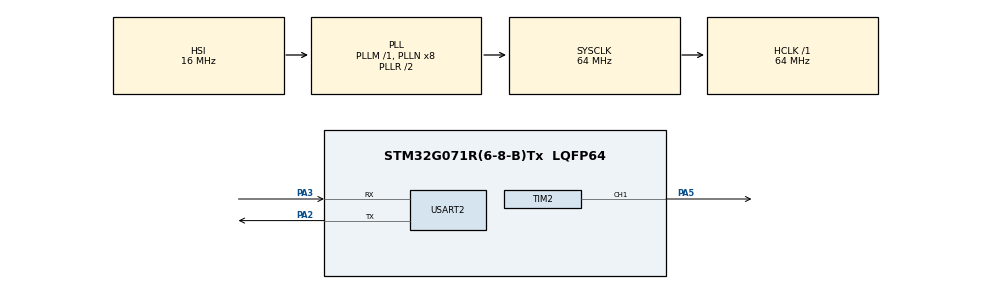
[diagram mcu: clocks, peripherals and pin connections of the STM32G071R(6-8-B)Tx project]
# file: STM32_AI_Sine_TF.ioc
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Mcu.Family=STM32G0
Mcu.Name=STM32G071R(6-8-B)Tx
Mcu.Package=LQFP64
PA2.Mode=Asynchronous
PA2.Signal=USART2_TX
PA3.Mode=Asynchronous
PA3.Signal=USART2_RX
PA5.Signal=S_TIM2_CH1_ETR
ProjectManager.HeapSize=0x200
ProjectManager.StackSize=0x400
ProjectManager.TargetToolchain=STM32CubeIDE
RCC.ADCFreq_Value=64000000
RCC.AHBFreq_Value=64000000
RCC.CortexFreq_Value=64000000
RCC.EXTERNAL_CLOCK_VALUE=48000
RCC.HCLKFreq_Value=64000000
RCC.HSE_VALUE=8000000
RCC.HSI_VALUE=16000000
RCC.LSE_VALUE=32768
RCC.SYSCLKFreq_VALUE=64000000
RCC.SYSCLKSource=RCC_SYSCLKSOURCE_PLLCLK
RCC.VCOOutputFreq_Value=128000000
SH.S_TIM2_CH1_ETR.0=TIM2_CH1,PWM Generation1 CH1
STMicroelectronics.X-CUBE-AI.10.2.0.ActivationBufferSizeList=2324
STMicroelectronics.X-CUBE-AI.10.2.0.ActivationBuffers=pool0
STMicroelectronics.X-CUBE-AI.10.2.0.ActivationNames=pool0
STMicroelectronics.X-CUBE-AI.10.2.0.ActivationSizes=AI_NETWORK_DATA_ACTIVATION_1_SIZE
STMicroelectronics.X-CUBE-AI.10.2.0.ApplicationCcDeviceJjApplication=ApplicationTemplate
STMicroelectronics.X-CUBE-AI.10.2.0.HeapSize=0x800
STMicroelectronics.X-CUBE-AI.10.2.0.InternalRamActivationBufferMaxSize=AI_NETWORK_DATA_ACTIVATIONS_SIZE
STMicroelectronics.X-CUBE-AI.10.2.0.LatestDirectoryUsed-8d1a59b6cb83f40a21b0c917e407ef7199938754835df7f124ed098826dc69b4=/home/montanab/Modelos
STMicroelectronics.X-CUBE-AI.10.2.0.MaximumNumberOfInputLayer=1
STMicroelectronics.X-CUBE-AI.10.2.0.MaximumNumberOfOutputLayer=1
STMicroelectronics.X-CUBE-AI.10.2.0.MaximumSizeOfInputLayer=1
STMicroelectronics.X-CUBE-AI.10.2.0.MaximumSizeOfOutputLayer=1
STMicroelectronics.X-CUBE-AI.10.2.0.ModelActualCompression-8d1a59b6cb83f40a21b0c917e407ef7199938754835df7f124ed098826dc69b4=0.0
STMicroelectronics.X-CUBE-AI.10.2.0.ModelCompression-8d1a59b6cb83f40a21b0c917e407ef7199938754835df7f124ed098826dc69b4=High
STMicroelectronics.X-CUBE-AI.10.2.0.ModelFlashOccupation-8d1a59b6cb83f40a21b0c917e407ef7199938754835df7f124ed098826dc69b4=18062
STMicroelectronics.X-CUBE-AI.10.2.0.ModelHashList=8d1a59b6cb83f40a21b0c917e407ef7199938754835df7f124ed098826dc69b4
STMicroelectronics.X-CUBE-AI.10.2.0.ModelKind-8d1a59b6cb83f40a21b0c917e407ef7199938754835df7f124ed098826dc69b4=TFLITE
STMicroelectronics.X-CUBE-AI.10.2.0.ModelMacc-8d1a59b6cb83f40a21b0c917e407ef7199938754835df7f124ed098826dc69b4=4481
STMicroelectronics.X-CUBE-AI.10.2.0.ModelName-8d1a59b6cb83f40a21b0c917e407ef7199938754835df7f124ed098826dc69b4=network
STMicroelectronics.X-CUBE-AI.10.2.0.ModelNameList=network
STMicroelectronics.X-CUBE-AI.10.2.0.ModelRamOccupation-8d1a59b6cb83f40a21b0c917e407ef7199938754835df7f124ed098826dc69b4=2324
STMicroelectronics.X-CUBE-AI.10.2.0.ModelStructureFile-8d1a59b6cb83f40a21b0c917e407ef7199938754835df7f124ed098826dc69b4=/home/montanab/Modelos/sine_model.tflite
STMicroelectronics.X-CUBE-AI.10.2.0.ModelType-8d1a59b6cb83f40a21b0c917e407ef7199938754835df7f124ed098826dc69b4=STM32Cube.AI MCU runtime
STMicroelectronics.X-CUBE-AI.10.2.0.ReadyForCodeGeneration=true
STMicroelectronics.X-CUBE-AI.10.2.0.StackSize=0x800
STMicroelectronics.X-CUBE-AI.10.2.0.WorkingBufferStartAddrList=0xFFFFFFFF
STMicroelectronics.X-CUBE-AI.10.2.0.XAaCUBEAaAICcArtificialOoIntelligenceJjCore=true
STMicroelectronics.X-CUBE-AI.10.2.0.copyWeightToRam-8d1a59b6cb83f40a21b0c917e407ef7199938754835df7f124ed098826dc69b4=false
STMicroelectronics.X-CUBE-AI.10.2.0.customLayerConfigEnabled-8d1a59b6cb83f40a21b0c917e407ef7199938754835df7f124ed098826dc69b4=false
STMicroelectronics.X-CUBE-AI.10.2.0.noOnnxIoTranspose-8d1a59b6cb83f40a21b0c917e407ef7199938754835df7f124ed098826dc69b4=false
STMicroelectronics.X-CUBE-AI.10.2.0.useInputAllocation-8d1a59b6cb83f40a21b0c917e407ef7199938754835df7f124ed098826dc69b4=true
STMicroelectronics.X-CUBE-AI.10.2.0.useOutputAllocation-8d1a59b6cb83f40a21b0c917e407ef7199938754835df7f124ed098826dc69b4=true
TIM2.Channel-PWM\ Generation1\ CH1=TIM_CHANNEL_1
TIM2.Period=255
USART2.VirtualMode-Asynchronous=VM_ASYNC
VP_STMicroelectronics.X-CUBE-AI_VS_ArtificialOoIntelligenceJjXAaCUBEAaAI_10.2.0.Mode=ArtificialOoIntelligenceJjXAaCUBEAaAI
VP_STMicroelectronics.X-CUBE-AI_VS_DeviceJjApplication_10.2.0.Mode=DeviceJjApplication
VP_TIM2_VS_ClockSourceINT.Mode=Internal
board=custom

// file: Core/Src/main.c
/* USER CODE BEGIN Header */
/**
 ******************************************************************************
 * @file           : main.c
 * @brief          : Main program body
 ******************************************************************************
 * @attention
 *
 * Copyright (c) 2026 STMicroelectronics.
 * All rights reserved.
 *
 * This software is licensed under terms that can be found in the LICENSE file
 * in the root directory of this software component.
 * If no LICENSE file comes with this software, it is provided AS-IS.
 *
 ******************************************************************************
 */
/* USER CODE END Header */
#include "main.h"
#include "app_x-cube-ai.h"

/* USER CODE BEGIN Includes */
#include "network.h"
#include "network_data.h"
#include <stdio.h>
/* USER CODE END Includes */

TIM_HandleTypeDef htim2;

UART_HandleTypeDef huart2;

/* USER CODE BEGIN PV */
ai_handle network;
float aiInData[AI_NETWORK_IN_1_SIZE];
float aiOutData[AI_NETWORK_OUT_1_SIZE];
ai_u8 activations[AI_NETWORK_DATA_ACTIVATIONS_SIZE];
ai_buffer * ai_input;
ai_buffer * ai_output;
/* USER CODE END PV */

void SystemClock_Config(void);
static void MX_GPIO_Init(void);
static void MX_TIM2_Init(void);
static void MX_USART2_UART_Init(void);
/* USER CODE BEGIN PFP */
int _write(int fd, char * ptr, int len)
{
	HAL_UART_Transmit(&huart2, (uint8_t *) ptr, len,    HAL_MAX_DELAY);
	return len;
}
/* USER CODE END PFP */

/* USER CODE BEGIN 0 */
static void AI_Init(void)
{
	ai_error err;

	/* Create a local array with the addresses of the activations buffers */
	const ai_handle act_addr[] = { activations };
	/* Create an instance of the model */
	err = ai_network_create_and_init(&network, act_addr, NULL);
	if (err.type != AI_ERROR_NONE) {
		printf("ai_network_create error - type=%d code=%d\r\n", err.type, err.code);
		Error_Handler();
	}
	ai_input = ai_network_inputs_get(network, NULL);
	ai_output = ai_network_outputs_get(network, NULL);
}

static void AI_Run(float *pIn, float *pOut)
{
	ai_i32 batch;
	ai_error err;

	/* Update IO handlers with the data payload */
	ai_input[0].data = AI_HANDLE_PTR(pIn);
	ai_output[0].data = AI_HANDLE_PTR(pOut);

	batch = ai_network_run(network, ai_input, ai_output);
	if (batch != 1) {
		err = ai_network_get_error(network);
		printf("AI ai_network_run error - type=%d code=%d\r\n", err.type, err.code);
		Error_Handler();
	}
}

/* USER CODE END 0 */

int main(void)
{

	/* USER CODE BEGIN 1 */
	float x_pos = 0.0f;
	float prediction;
	/* USER CODE END 1 */

	/* MCU Configuration--------------------------------------------------------*/

	/* Reset of all peripherals, Initializes the Flash interface and the Systick. */
	HAL_Init();

	/* Configure the system clock */
	SystemClock_Config();

	/* Initialize all configured peripherals */
	MX_GPIO_Init();
	MX_TIM2_Init();
	MX_USART2_UART_Init();
	//MX_X_CUBE_AI_Init();
	/* USER CODE BEGIN 2 */
	AI_Init();
	HAL_TIM_PWM_Start(&htim2, TIM_CHANNEL_1);
	/* USER CODE END 2 */

	/* Infinite loop */
	while (1)
	{

		//MX_X_CUBE_AI_Process();
		/* USER CODE BEGIN 3 */
		aiInData[0] = x_pos;
		printf("Running inference\r\n");
		AI_Run(aiInData, aiOutData);
		/* Output results */
		printf("Input: %8.6f. Calculated sine value: %8.6f \r\n", x_pos, aiOutData[0]);

		prediction = aiOutData[0];
		int pwm_val = (int)((prediction + 1.0f) * 127.5f); // Map to 0-255
		__HAL_TIM_SET_COMPARE(&htim2, TIM_CHANNEL_1, pwm_val);
		x_pos += 0.05f;
		if (x_pos > (2.0f * 3.141516)) x_pos = 0;
		HAL_Delay(20);

	}
	/* USER CODE END 3 */
}

void SystemClock_Config(void)
{
	RCC_OscInitTypeDef RCC_OscInitStruct = {0};
	RCC_ClkInitTypeDef RCC_ClkInitStruct = {0};

	/** Configure the main internal regulator output voltage
	 */
	HAL_PWREx_ControlVoltageScaling(PWR_REGULATOR_VOLTAGE_SCALE1);

	/** Initializes the RCC Oscillators according to the specified parameters
	 * in the RCC_OscInitTypeDef structure.
	 */
	RCC_OscInitStruct.OscillatorType = RCC_OSCILLATORTYPE_HSI;
	RCC_OscInitStruct.HSIState = RCC_HSI_ON;
	RCC_OscInitStruct.HSIDiv = RCC_HSI_DIV1;
	RCC_OscInitStruct.HSICalibrationValue = RCC_HSICALIBRATION_DEFAULT;
	RCC_OscInitStruct.PLL.PLLState = RCC_PLL_ON;
	RCC_OscInitStruct.PLL.PLLSource = RCC_PLLSOURCE_HSI;
	RCC_OscInitStruct.PLL.PLLM = RCC_PLLM_DIV1;
	RCC_OscInitStruct.PLL.PLLN = 8;
	RCC_OscInitStruct.PLL.PLLP = RCC_PLLP_DIV2;
	RCC_OscInitStruct.PLL.PLLQ = RCC_PLLQ_DIV2;
	RCC_OscInitStruct.PLL.PLLR = RCC_PLLR_DIV2;
	if (HAL_RCC_OscConfig(&RCC_OscInitStruct) != HAL_OK)
	{
		Error_Handler();
	}

	/** Initializes the CPU, AHB and APB buses clocks
	 */
	RCC_ClkInitStruct.ClockType = RCC_CLOCKTYPE_HCLK|RCC_CLOCKTYPE_SYSCLK
			|RCC_CLOCKTYPE_PCLK1;
	RCC_ClkInitStruct.SYSCLKSource = RCC_SYSCLKSOURCE_PLLCLK;
	RCC_ClkInitStruct.AHBCLKDivider = RCC_SYSCLK_DIV1;
	RCC_ClkInitStruct.APB1CLKDivider = RCC_HCLK_DIV1;

	if (HAL_RCC_ClockConfig(&RCC_ClkInitStruct, FLASH_LATENCY_2) != HAL_OK)
	{
		Error_Handler();
	}
}

static void MX_TIM2_Init(void)
{

	TIM_ClockConfigTypeDef sClockSourceConfig = {0};
	TIM_MasterConfigTypeDef sMasterConfig = {0};
	TIM_OC_InitTypeDef sConfigOC = {0};

	htim2.Instance = TIM2;
	htim2.Init.Prescaler = 0;
	htim2.Init.CounterMode = TIM_COUNTERMODE_UP;
	htim2.Init.Period = 255;
	htim2.Init.ClockDivision = TIM_CLOCKDIVISION_DIV1;
	htim2.Init.AutoReloadPreload = TIM_AUTORELOAD_PRELOAD_DISABLE;
	if (HAL_TIM_Base_Init(&htim2) != HAL_OK)
	{
		Error_Handler();
	}
	sClockSourceConfig.ClockSource = TIM_CLOCKSOURCE_INTERNAL;
	if (HAL_TIM_ConfigClockSource(&htim2, &sClockSourceConfig) != HAL_OK)
	{
		Error_Handler();
	}
	if (HAL_TIM_PWM_Init(&htim2) != HAL_OK)
	{
		Error_Handler();
	}
	sMasterConfig.MasterOutputTrigger = TIM_TRGO_RESET;
	sMasterConfig.MasterSlaveMode = TIM_MASTERSLAVEMODE_DISABLE;
	if (HAL_TIMEx_MasterConfigSynchronization(&htim2, &sMasterConfig) != HAL_OK)
	{
		Error_Handler();
	}
	sConfigOC.OCMode = TIM_OCMODE_PWM1;
	sConfigOC.Pulse = 0;
	sConfigOC.OCPolarity = TIM_OCPOLARITY_HIGH;
	sConfigOC.OCFastMode = TIM_OCFAST_DISABLE;
	if (HAL_TIM_PWM_ConfigChannel(&htim2, &sConfigOC, TIM_CHANNEL_1) != HAL_OK)
	{
		Error_Handler();
	}
	HAL_TIM_MspPostInit(&htim2);

}

static void MX_USART2_UART_Init(void)
{

	huart2.Instance = USART2;
	huart2.Init.BaudRate = 115200;
	huart2.Init.WordLength = UART_WORDLENGTH_8B;
	huart2.Init.StopBits = UART_STOPBITS_1;
	huart2.Init.Parity = UART_PARITY_NONE;
	huart2.Init.Mode = UART_MODE_TX_RX;
	huart2.Init.HwFlowCtl = UART_HWCONTROL_NONE;
	huart2.Init.OverSampling = UART_OVERSAMPLING_16;
	huart2.Init.OneBitSampling = UART_ONE_BIT_SAMPLE_DISABLE;
	huart2.Init.ClockPrescaler = UART_PRESCALER_DIV1;
	huart2.AdvancedInit.AdvFeatureInit = UART_ADVFEATURE_NO_INIT;
	if (HAL_UART_Init(&huart2) != HAL_OK)
	{
		Error_Handler();
	}
	if (HAL_UARTEx_SetTxFifoThreshold(&huart2, UART_TXFIFO_THRESHOLD_1_8) != HAL_OK)
	{
		Error_Handler();
	}
	if (HAL_UARTEx_SetRxFifoThreshold(&huart2, UART_RXFIFO_THRESHOLD_1_8) != HAL_OK)
	{
		Error_Handler();
	}
	if (HAL_UARTEx_DisableFifoMode(&huart2) != HAL_OK)
	{
		Error_Handler();
	}

}

static void MX_GPIO_Init(void)
{

	/* GPIO Ports Clock Enable */
	__HAL_RCC_GPIOA_CLK_ENABLE();

}

void Error_Handler(void)
{
	__disable_irq();
	while (1)
	{
	}
}
